# PIC18F25Q10 register map
Vendor: Microchip
Architecture 18xxxx. Special function registers and configuration words.
Registers are 8-bit, read-write, reset 0x0 unless marked. A register's access mark holds for its fields unless they carry their own. Addresses are absolute, and some are shared; only a register's first bit layout is shown; lines under a group give offsets from that group; [hi:lo] are bit positions; {n}, {i} and the like mark numbered series; 'fields as' and 'values as' point back to an identical list; <NAME> marks a mode.

## Further device data
pins=1: VPP/MCLR_n/ICD_n/IOCE3/RE3; 2: ANA0/C1IN0-/C2IN0-/IOCA0/RA0; 3: ANA1/C1IN1-/C2IN1-/IOCA1/RA1; 4: DAC1OUT1/VREF-/ANA2/C1IN0+/C2IN0+/IOCA2/RA2; 5: VREF+/ANA3/C1IN1+/IOCA3/RA3; 6: ANA4/IOCA4/RA4; 7: ANA5/IOCA5/RA5; 8: AVSS/VSS; 9: CLKIN/OSC1/ANA7/IOCA7/RA7; 10: OSC2/CLKOUT/ANA6/IOCA6/RA6; 11: SOSCO/ANC0/IOCC0/RC0; 12: SOSCI/ANC1/IOCC1/RC1; 13: ANC2/IOCC2/RC2; 14: SMB_I2C/ANC3/IOCC3/RC3; 15: SMB_I2C/ANC4/IOCC4/RC4; 16: ANC5/IOCC5/RC5; 17: ANC6/IOCC6/RC6; 18: ANC7/IOCC7/RC7; 19: VSS/VSEL0; 20: AVDD/VDD; 21: ZCD/ANB0/C2IN1+/IOCB0/RB0; 22: ANB1/C1IN3-/C2IN3-/SMB_I2C/IOCB1/RB1; 23: ANB2/SMB_I2C/IOCB2/RB2; 24: ANB3/C1IN2-/C2IN2-/IOCB3/RB3; 25: ANB4/IOCB4/RB4; 26: ANB5/IOCB5/RB5; 27: ICSPCLK/ICDCLK/ANB6/IOCB6/RB6; 28: ICSPDAT/ICDDAT/DAC1OUT2/ANB7/IOCB7/RB7

## wdt_windowed
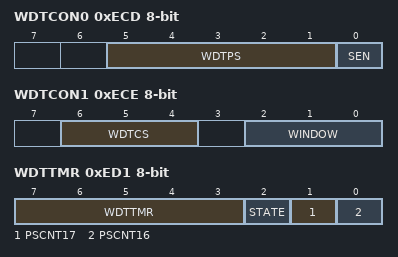
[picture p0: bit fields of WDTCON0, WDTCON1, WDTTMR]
0xECD WDTCON0 reset not defined — (power-on value --qqqqq0)
  [5:1] WDTPS, [0] SEN
0xECE WDTCON1 reset not defined — (power-on value -qqq-qqq)
  [6:4] WDTCS, [2:0] WINDOW
0xECF WDTPSL ro
  [7:0] PSCNT
0xED0 WDTPSH ro
  [7:0] PSCNT
0xED1 WDTTMR ro reset not defined — (power-on value xxxxx000)
  [7:3] WDTTMR, [2] STATE, [1] PSCNT17, [0] PSCNT16

## DOS_02264_pmd_mid8_v1_xxK40_8Bit
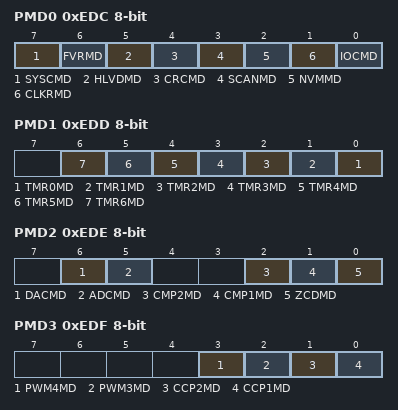
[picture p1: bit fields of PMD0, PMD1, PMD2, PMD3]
0xEDC PMD0 reset not defined — (power-on value 00x00000)
  [7] SYSCMD, [6] FVRMD, [5] HLVDMD, [4] CRCMD, [3] SCANMD, [2] NVMMD, [1] CLKRMD, [0] IOCMD
0xEDD PMD1
  [n] TMR{n}MD (n=0..6)
0xEDE PMD2
  [6] DACMD, [5] ADCMD, [2] CMP2MD, [1] CMP1MD, [0] ZCDMD
0xEDF PMD3
  [3] PWM4MD, [2] PWM3MD, [1] CCP2MD, [0] CCP1MD
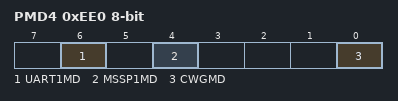
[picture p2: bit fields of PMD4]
0xEE0 PMD4
  [6] UART1MD, [4] MSSP1MD, [0] CWGMD
0xEE1 PMD5
  [0] DSMMD

## DOS_xxxxx_pps_mid_v2_output_xxK40_8bit
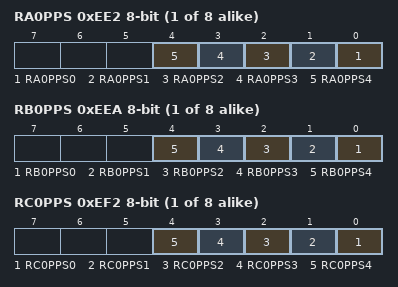
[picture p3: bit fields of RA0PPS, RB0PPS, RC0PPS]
{0xEE2+i} RA{i}PPS (i=0..7)
  [n] RA{i}PPS{n} (n=0..4)
{0xEEA+i} RB{i}PPS (i=0..7)
  [n] RB{i}PPS{n} (n=0..4)
{0xEF2+i} RC{i}PPS (i=0..7)
  [n] RC{i}PPS{n} (n=0..4)

## IOC___Port_Control
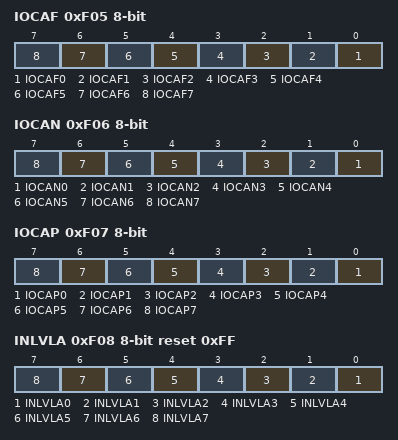
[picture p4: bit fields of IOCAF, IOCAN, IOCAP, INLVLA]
0xF05 IOCAF
  [n] IOCAF{n} (n=0..7)
0xF06 IOCAN
  [n] IOCAN{n} (n=0..7)
0xF07 IOCAP
  [n] IOCAP{n} (n=0..7)
0xF08 INLVLA reset 0xFF
  [n] INLVLA{n} (n=0..7)
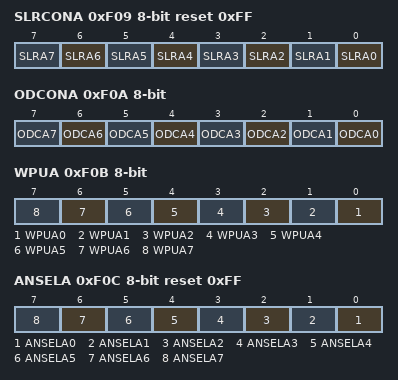
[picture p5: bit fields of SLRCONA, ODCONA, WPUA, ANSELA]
0xF09 SLRCONA reset 0xFF
  [n] SLRA{n} (n=0..7)
0xF0A ODCONA
  [n] ODCA{n} (n=0..7)
0xF0B WPUA
  [n] WPUA{n} (n=0..7)
0xF0C ANSELA reset 0xFF
  [n] ANSELA{n} (n=0..7)
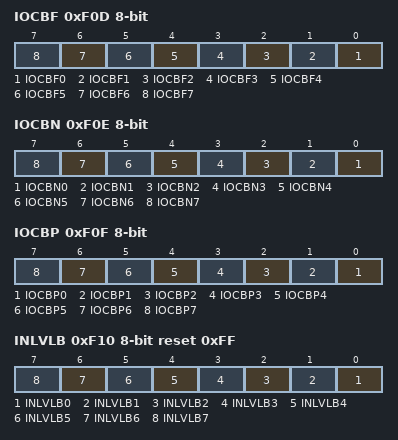
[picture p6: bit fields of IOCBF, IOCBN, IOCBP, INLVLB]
0xF0D IOCBF
  [n] IOCBF{n} (n=0..7)
0xF0E IOCBN
  [n] IOCBN{n} (n=0..7)
0xF0F IOCBP
  [n] IOCBP{n} (n=0..7)
0xF10 INLVLB reset 0xFF
  [n] INLVLB{n} (n=0..7)
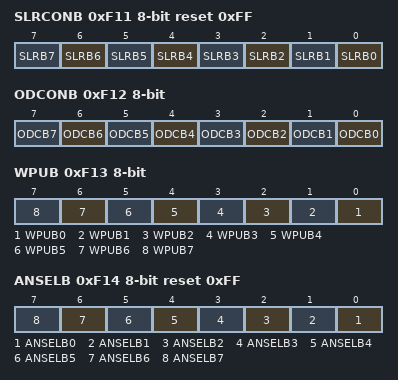
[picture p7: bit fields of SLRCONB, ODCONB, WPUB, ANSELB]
0xF11 SLRCONB reset 0xFF
  [n] SLRB{n} (n=0..7)
0xF12 ODCONB
  [n] ODCB{n} (n=0..7)
0xF13 WPUB
  [n] WPUB{n} (n=0..7)
0xF14 ANSELB reset 0xFF
  [n] ANSELB{n} (n=0..7)
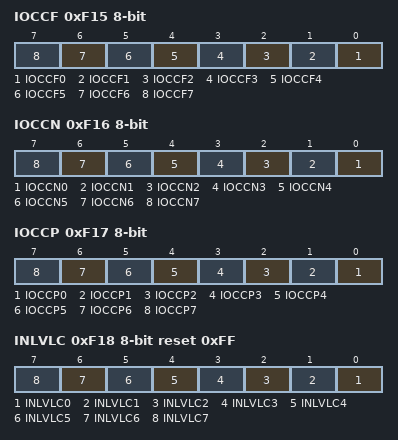
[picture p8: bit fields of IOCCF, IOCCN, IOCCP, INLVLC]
0xF15 IOCCF
  [n] IOCCF{n} (n=0..7)
0xF16 IOCCN
  [n] IOCCN{n} (n=0..7)
0xF17 IOCCP
  [n] IOCCP{n} (n=0..7)
0xF18 INLVLC reset 0xFF
  [n] INLVLC{n} (n=0..7)
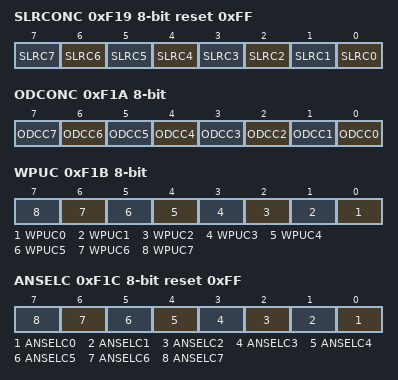
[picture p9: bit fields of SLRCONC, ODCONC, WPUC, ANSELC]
0xF19 SLRCONC reset 0xFF
  [n] SLRC{n} (n=0..7)
0xF1A ODCONC
  [n] ODCC{n} (n=0..7)
0xF1B WPUC
  [n] WPUC{n} (n=0..7)
0xF1C ANSELC reset 0xFF
  [n] ANSELC{n} (n=0..7)
0xF22 IOCEF
  [3] IOCEF3
0xF23 IOCEN
  [3] IOCEN3
0xF24 IOCEP
  [3] IOCEP3
0xF25 INLVLE reset 0x8
  [3] INLVLE3
0xF28 WPUE
  [3] WPUE3
